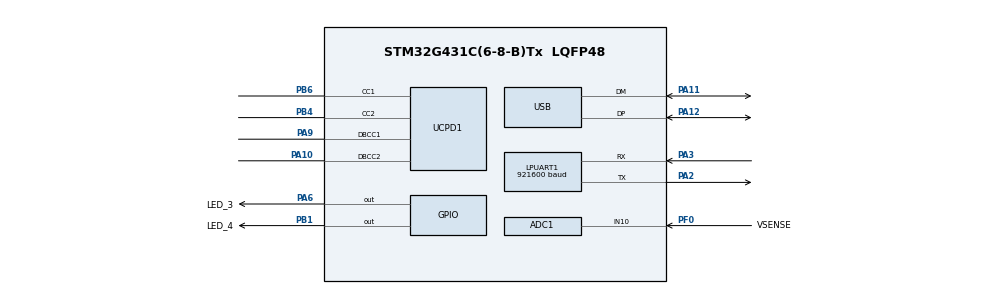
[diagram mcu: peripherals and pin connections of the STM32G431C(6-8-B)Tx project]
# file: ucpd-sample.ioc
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ADC1.Channel-0\#ChannelRegularConversion=ADC_CHANNEL_10
ADC1.ClockPrescaler=ADC_CLOCK_SYNC_PCLK_DIV4
ADC1.ContinuousConvMode=ENABLE
ADC1.NbrOfConversionFlag=1
ADC1.OffsetNumber-0\#ChannelRegularConversion=ADC_OFFSET_NONE
ADC1.Overrun=ADC_OVR_DATA_OVERWRITTEN
ADC1.Rank-0\#ChannelRegularConversion=1
ADC1.SamplingTime-0\#ChannelRegularConversion=ADC_SAMPLETIME_247CYCLES_5
ADC1.master=1
Dma.LPUART1_TX.0.Direction=DMA_MEMORY_TO_PERIPH
Dma.LPUART1_TX.0.EventEnable=DISABLE
Dma.LPUART1_TX.0.Instance=DMA1_Channel1
Dma.LPUART1_TX.0.MemDataAlignment=DMA_MDATAALIGN_BYTE
Dma.LPUART1_TX.0.MemInc=DMA_MINC_ENABLE
Dma.LPUART1_TX.0.Mode=DMA_NORMAL
Dma.LPUART1_TX.0.PeriphDataAlignment=DMA_PDATAALIGN_BYTE
Dma.LPUART1_TX.0.PeriphInc=DMA_PINC_DISABLE
Dma.LPUART1_TX.0.Polarity=HAL_DMAMUX_REQ_GEN_RISING
Dma.LPUART1_TX.0.Priority=DMA_PRIORITY_LOW
Dma.LPUART1_TX.0.RequestNumber=1
Dma.LPUART1_TX.0.SignalID=NONE
Dma.LPUART1_TX.0.SyncEnable=DISABLE
Dma.LPUART1_TX.0.SyncPolarity=HAL_DMAMUX_SYNC_NO_EVENT
Dma.LPUART1_TX.0.SyncRequestNumber=1
Dma.LPUART1_TX.0.SyncSignalID=NONE
Dma.Request0=LPUART1_TX
Dma.Request1=UCPD1_RX
Dma.Request2=UCPD1_TX
Dma.UCPD1_RX.1.Direction=DMA_PERIPH_TO_MEMORY
Dma.UCPD1_RX.1.EventEnable=DISABLE
Dma.UCPD1_RX.1.Instance=DMA1_Channel2
Dma.UCPD1_RX.1.MemDataAlignment=DMA_MDATAALIGN_BYTE
Dma.UCPD1_RX.1.MemInc=DMA_MINC_ENABLE
Dma.UCPD1_RX.1.Mode=DMA_NORMAL
Dma.UCPD1_RX.1.PeriphDataAlignment=DMA_PDATAALIGN_BYTE
Dma.UCPD1_RX.1.PeriphInc=DMA_PINC_DISABLE
Dma.UCPD1_RX.1.Polarity=HAL_DMAMUX_REQ_GEN_RISING
Dma.UCPD1_RX.1.Priority=DMA_PRIORITY_LOW
Dma.UCPD1_RX.1.RequestNumber=1
Dma.UCPD1_RX.1.SignalID=NONE
Dma.UCPD1_RX.1.SyncEnable=DISABLE
Dma.UCPD1_RX.1.SyncPolarity=HAL_DMAMUX_SYNC_NO_EVENT
Dma.UCPD1_RX.1.SyncRequestNumber=1
Dma.UCPD1_RX.1.SyncSignalID=NONE
Dma.UCPD1_TX.2.Direction=DMA_MEMORY_TO_PERIPH
Dma.UCPD1_TX.2.EventEnable=DISABLE
Dma.UCPD1_TX.2.Instance=DMA1_Channel3
Dma.UCPD1_TX.2.MemDataAlignment=DMA_MDATAALIGN_BYTE
Dma.UCPD1_TX.2.MemInc=DMA_MINC_ENABLE
Dma.UCPD1_TX.2.Mode=DMA_NORMAL
Dma.UCPD1_TX.2.PeriphDataAlignment=DMA_PDATAALIGN_BYTE
Dma.UCPD1_TX.2.PeriphInc=DMA_PINC_DISABLE
Dma.UCPD1_TX.2.Polarity=HAL_DMAMUX_REQ_GEN_RISING
Dma.UCPD1_TX.2.Priority=DMA_PRIORITY_LOW
Dma.UCPD1_TX.2.RequestNumber=1
Dma.UCPD1_TX.2.SignalID=NONE
Dma.UCPD1_TX.2.SyncEnable=DISABLE
Dma.UCPD1_TX.2.SyncPolarity=HAL_DMAMUX_SYNC_NO_EVENT
Dma.UCPD1_TX.2.SyncRequestNumber=1
Dma.UCPD1_TX.2.SyncSignalID=NONE
FREERTOS.Tasks01=defaultTask,24,128,StartDefaultTask,Default,NULL,Dynamic,NULL,NULL
FREERTOS.configTOTAL_HEAP_SIZE=7000
FREERTOS.configUSE_NEWLIB_REENTRANT=1
GUI_INTERFACE.HWBoardVersionName=G4_UCPD01
GUI_INTERFACE.PDTypeName=Sink
LPUART1.BaudRate=921600
Mcu.Family=STM32G4
Mcu.Name=STM32G431C(6-8-B)Tx
Mcu.Package=LQFP48
Mcu.UserConstants=VDDA_APPLI,3300
NVIC.DMA1_Channel1_IRQn=true\:5\:0\:false\:false\:true\:true\:false\:true\:true
NVIC.DMA1_Channel2_IRQn=true\:5\:0\:false\:false\:true\:true\:false\:true\:true
NVIC.DMA1_Channel3_IRQn=true\:5\:0\:false\:false\:true\:true\:false\:true\:true
NVIC.LPUART1_IRQn=true\:5\:0\:false\:false\:true\:true\:false\:true\:true
NVIC.PriorityGroup=NVIC_PRIORITYGROUP_4
NVIC.UCPD1_IRQn=true\:5\:0\:false\:false\:true\:true\:true\:false\:true
PA10.Mode=EnableDeadBattery
PA10.Signal=UCPD1_DBCC2
PA11.Mode=Device
PA11.Signal=USB_DM
PA12.Mode=Device
PA12.Signal=USB_DP
PA13.Mode=Serial_Wire
PA13.Signal=SYS_JTMS-SWDIO
PA14.Mode=Serial_Wire
PA14.Signal=SYS_JTCK-SWCLK
PA2.Mode=Asynchronous
PA2.Signal=LPUART1_TX
PA3.Mode=Asynchronous
PA3.Signal=LPUART1_RX
PA6.GPIO_Label=LED_3
PA6.PinState=GPIO_PIN_SET
PA6.Signal=GPIO_Output
PA9.Mode=EnableDeadBattery
PA9.Signal=UCPD1_DBCC1
PB1.GPIO_Label=LED_4
PB1.PinState=GPIO_PIN_SET
PB1.Signal=GPIO_Output
PB4.Mode=Sink_AllSignals
PB4.Signal=UCPD1_CC2
PB6.Mode=Sink_AllSignals
PB6.Signal=UCPD1_CC1
PF0-OSC_IN.GPIO_Label=VSENSE
PF0-OSC_IN.Mode=IN10-Single-Ended
PF0-OSC_IN.Signal=ADC1_IN10
ProjectManager.HeapSize=0x500
ProjectManager.StackSize=0x400
ProjectManager.TargetToolchain=CMake
RCC.AHBFreq_Value=16000000
RCC.APB1Freq_Value=16000000
RCC.APB1TimFreq_Value=16000000
RCC.APB2Freq_Value=16000000
RCC.APB2TimFreq_Value=16000000
RCC.CortexFreq_Value=16000000
RCC.EXTERNAL_CLOCK_VALUE=12288000
RCC.HCLKFreq_Value=16000000
RCC.HSE_VALUE=8000000
RCC.HSI48_VALUE=48000000
RCC.HSI_VALUE=16000000
RCC.LSE_VALUE=32768
RCC.PLLN=12
RCC.PLLQ=RCC_PLLQ_DIV4
RCC.SYSCLKFreq_VALUE=16000000
RCC.USBFreq_Value=48000000
RCC.VCOOutputFreq_Value=192000000
USBPD.PORT0_NB_SINKPDO=4
USBPD.USBPD_PORT0_PDO_SNK_BATTERY_SET_MAX_VOLTAGE_3=15000
USBPD.USBPD_PORT0_PDO_SNK_BATTERY_SET_OP_POWER_3=1000
USBPD.USBPD_PORT0_PDO_SNK_FIXED_SET_OP_CURRENT_0=3000
USBPD.USBPD_PORT0_PDO_SNK_FIXED_SET_OP_CURRENT_1=2000
USBPD.USBPD_PORT0_PDO_SNK_FIXED_SET_OP_CURRENT_2=2000
USBPD.USBPD_PORT0_PDO_SNK_FIXED_SET_VOLTAGE_1=9000
USBPD.USBPD_PORT0_PDO_SNK_FIXED_SET_VOLTAGE_2=15000
USBPD.USBPD_PORT0_PDO_SNK_NB=4
USBPD.USBPD_PORT0_PDO_SNK_TYPE_2=USBPD_PDO_TYPE_FIXED
USBPD.USBPD_PORT0_PDO_SNK_TYPE_3=USBPD_PDO_TYPE_VARIABLE
USBPD.USBPD_PORT0_PDO_SNK_VARIABLE_SET_MAX_VOLTAGE_2=15000
USBPD.USBPD_PORT0_PDO_SNK_VARIABLE_SET_MIN_VOLTAGE_3=15000
USBPD.USBPD_PORT0_PDO_SNK_VARIABLE_SET_OP_CURRENT_2=1500
USBPD.USBPD_PORT0_PDO_SNK_VARIABLE_SET_OP_CURRENT_3=1000
VP_FREERTOS_VS_CMSIS_V2.Mode=CMSIS_V2
VP_GUI_INTERFACE_VS_gui_interface.Mode=GUI_INTERFACE
VP_SYS_VS_DBSignals.Mode=DisableDeadBatterySignals
VP_TRACER_EMB_VS_traceremb_lpuart1.Mode=TRACER_EMB_LPUART1
VP_USBPD_VS_PD3MINSNK.Mode=PD3_Min_Snk
VP_USBPD_VS_USBPD1.Mode=USBPD_P0
VP_USBPD_VS_usbpd_tim1.Mode=TIM1
VP_USBPD_VS_usbpd_traceremb.Mode=TRACER_EMB
board=custom

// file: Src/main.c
/* USER CODE BEGIN Header */
/**
  ******************************************************************************
  * @file           : main.c
  * @brief          : Main program body
  ******************************************************************************
  * @attention
  *
  * Copyright (c) 2024 STMicroelectronics.
  * All rights reserved.
  *
  * This software is licensed under terms that can be found in the LICENSE file
  * in the root directory of this software component.
  * If no LICENSE file comes with this software, it is provided AS-IS.
  *
  ******************************************************************************
  */
/* USER CODE END Header */
#include "main.h"
#include "cmsis_os.h"
#include "usbpd.h"

PCD_HandleTypeDef hpcd_USB_FS;

/* Definitions for defaultTask */
osThreadId_t defaultTaskHandle;
const osThreadAttr_t defaultTask_attributes = {
  .name = "defaultTask",
  .priority = (osPriority_t) osPriorityNormal,
  .stack_size = 128 * 4
};

void SystemClock_Config(void);
static void MX_GPIO_Init(void);
static void MX_DMA_Init(void);
static void MX_LPUART1_UART_Init(void);
static void MX_USB_PCD_Init(void);
static void MX_UCPD1_Init(void);
static void MX_ADC1_Init(void);
void StartDefaultTask(void *argument);

int main(void)
{

  /* MCU Configuration--------------------------------------------------------*/

  /* Reset of all peripherals, Initializes the Flash interface and the Systick. */
  HAL_Init();

  /* Configure the system clock */
  SystemClock_Config();

  /* Initialize all configured peripherals */
  MX_GPIO_Init();
  MX_DMA_Init();
  MX_LPUART1_UART_Init();
  MX_USB_PCD_Init();
  HAL_Delay(1000);
  MX_UCPD1_Init();
  MX_ADC1_Init();

  /* Init scheduler */
  osKernelInitialize();
  /* USBPD initialisation ---------------------------------*/
  // MX_USBPD_Init();

  /* Create the thread(s) */
  /* creation of defaultTask */
  defaultTaskHandle = osThreadNew(StartDefaultTask, NULL, &defaultTask_attributes);

  /* Start scheduler */
  osKernelStart();

  /* We should never get here as control is now taken by the scheduler */

  /* Infinite loop */
  while (1)
  {

  }
}

void SystemClock_Config(void)
{
  LL_FLASH_SetLatency(LL_FLASH_LATENCY_0);
  while(LL_FLASH_GetLatency() != LL_FLASH_LATENCY_0)
  {
  }
  LL_PWR_SetRegulVoltageScaling(LL_PWR_REGU_VOLTAGE_SCALE1);
  LL_RCC_HSI_Enable();
   /* Wait till HSI is ready */
  while(LL_RCC_HSI_IsReady() != 1)
  {
  }

  LL_RCC_HSI_SetCalibTrimming(64);
  LL_RCC_PLL_ConfigDomain_48M(LL_RCC_PLLSOURCE_HSI, LL_RCC_PLLM_DIV_1, 12, LL_RCC_PLLQ_DIV_4);
  LL_RCC_PLL_EnableDomain_48M();
  LL_RCC_PLL_Enable();
   /* Wait till PLL is ready */
  while(LL_RCC_PLL_IsReady() != 1)
  {
  }

  LL_RCC_SetSysClkSource(LL_RCC_SYS_CLKSOURCE_HSI);
   /* Wait till System clock is ready */
  while(LL_RCC_GetSysClkSource() != LL_RCC_SYS_CLKSOURCE_STATUS_HSI)
  {
  }

  /* Set AHB prescaler*/
  LL_RCC_SetAHBPrescaler(LL_RCC_SYSCLK_DIV_1);
  LL_RCC_SetAPB1Prescaler(LL_RCC_APB1_DIV_1);
  LL_RCC_SetAPB2Prescaler(LL_RCC_APB2_DIV_1);
  LL_SetSystemCoreClock(16000000);

   /* Update the time base */
  if (HAL_InitTick (TICK_INT_PRIORITY) != HAL_OK)
  {
    Error_Handler();
  }
}

static void MX_ADC1_Init(void)
{

  LL_ADC_InitTypeDef ADC_InitStruct = {0};
  LL_ADC_REG_InitTypeDef ADC_REG_InitStruct = {0};
  LL_ADC_CommonInitTypeDef ADC_CommonInitStruct = {0};

  LL_GPIO_InitTypeDef GPIO_InitStruct = {0};

  LL_RCC_SetADCClockSource(LL_RCC_ADC12_CLKSOURCE_SYSCLK);

  /* Peripheral clock enable */
  LL_AHB2_GRP1_EnableClock(LL_AHB2_GRP1_PERIPH_ADC12);

  LL_AHB2_GRP1_EnableClock(LL_AHB2_GRP1_PERIPH_GPIOF);
  /**ADC1 GPIO Configuration
  PF0-OSC_IN   ------> ADC1_IN10
  */
  GPIO_InitStruct.Pin = VSENSE_Pin;
  GPIO_InitStruct.Mode = LL_GPIO_MODE_ANALOG;
  GPIO_InitStruct.Pull = LL_GPIO_PULL_NO;
  LL_GPIO_Init(VSENSE_GPIO_Port, &GPIO_InitStruct);

  /** Common config
  */
  ADC_InitStruct.Resolution = LL_ADC_RESOLUTION_12B;
  ADC_InitStruct.DataAlignment = LL_ADC_DATA_ALIGN_RIGHT;
  ADC_InitStruct.LowPowerMode = LL_ADC_LP_MODE_NONE;
  LL_ADC_Init(ADC1, &ADC_InitStruct);
  ADC_REG_InitStruct.TriggerSource = LL_ADC_REG_TRIG_SOFTWARE;
  ADC_REG_InitStruct.SequencerLength = LL_ADC_REG_SEQ_SCAN_DISABLE;
  ADC_REG_InitStruct.SequencerDiscont = LL_ADC_REG_SEQ_DISCONT_DISABLE;
  ADC_REG_InitStruct.ContinuousMode = LL_ADC_REG_CONV_CONTINUOUS;
  ADC_REG_InitStruct.DMATransfer = LL_ADC_REG_DMA_TRANSFER_NONE;
  ADC_REG_InitStruct.Overrun = LL_ADC_REG_OVR_DATA_OVERWRITTEN;
  LL_ADC_REG_Init(ADC1, &ADC_REG_InitStruct);
  LL_ADC_SetGainCompensation(ADC1, 0);
  LL_ADC_SetOverSamplingScope(ADC1, LL_ADC_OVS_DISABLE);
  ADC_CommonInitStruct.CommonClock = LL_ADC_CLOCK_SYNC_PCLK_DIV4;
  ADC_CommonInitStruct.Multimode = LL_ADC_MULTI_INDEPENDENT;
  LL_ADC_CommonInit(__LL_ADC_COMMON_INSTANCE(ADC1), &ADC_CommonInitStruct);

  /* Disable ADC deep power down (enabled by default after reset state) */
  LL_ADC_DisableDeepPowerDown(ADC1);
  /* Enable ADC internal voltage regulator */
  LL_ADC_EnableInternalRegulator(ADC1);
  /* Delay for ADC internal voltage regulator stabilization. */
  /* Compute number of CPU cycles to wait for, from delay in us. */
  /* Note: Variable divided by 2 to compensate partially */
  /* CPU processing cycles (depends on compilation optimization). */
  /* Note: If system core clock frequency is below 200kHz, wait time */
  /* is only a few CPU processing cycles. */
  uint32_t wait_loop_index;
  wait_loop_index = ((LL_ADC_DELAY_INTERNAL_REGUL_STAB_US * (SystemCoreClock / (100000 * 2))) / 10);
  while(wait_loop_index != 0)
  {
    wait_loop_index--;
  }

  /** Configure Regular Channel
  */
  LL_ADC_REG_SetSequencerRanks(ADC1, LL_ADC_REG_RANK_1, LL_ADC_CHANNEL_10);
  LL_ADC_SetChannelSamplingTime(ADC1, LL_ADC_CHANNEL_10, LL_ADC_SAMPLINGTIME_247CYCLES_5);
  LL_ADC_SetChannelSingleDiff(ADC1, LL_ADC_CHANNEL_10, LL_ADC_SINGLE_ENDED);
  /* USER CODE BEGIN ADC1_Init 2 */
  LL_ADC_StartCalibration(ADC1, LL_ADC_SINGLE_ENDED);
  LL_ADC_REG_StartConversion(ADC1);
  /* USER CODE END ADC1_Init 2 */

}

static void MX_LPUART1_UART_Init(void)
{

  LL_LPUART_InitTypeDef LPUART_InitStruct = {0};

  LL_GPIO_InitTypeDef GPIO_InitStruct = {0};

  LL_RCC_SetLPUARTClockSource(LL_RCC_LPUART1_CLKSOURCE_PCLK1);

  /* Peripheral clock enable */
  LL_APB1_GRP2_EnableClock(LL_APB1_GRP2_PERIPH_LPUART1);

  LL_AHB2_GRP1_EnableClock(LL_AHB2_GRP1_PERIPH_GPIOA);
  /**LPUART1 GPIO Configuration
  PA2   ------> LPUART1_TX
  PA3   ------> LPUART1_RX
  */
  GPIO_InitStruct.Pin = LL_GPIO_PIN_2;
  GPIO_InitStruct.Mode = LL_GPIO_MODE_ALTERNATE;
  GPIO_InitStruct.Speed = LL_GPIO_SPEED_FREQ_LOW;
  GPIO_InitStruct.OutputType = LL_GPIO_OUTPUT_PUSHPULL;
  GPIO_InitStruct.Pull = LL_GPIO_PULL_NO;
  GPIO_InitStruct.Alternate = LL_GPIO_AF_12;
  LL_GPIO_Init(GPIOA, &GPIO_InitStruct);

  GPIO_InitStruct.Pin = LL_GPIO_PIN_3;
  GPIO_InitStruct.Mode = LL_GPIO_MODE_ALTERNATE;
  GPIO_InitStruct.Speed = LL_GPIO_SPEED_FREQ_LOW;
  GPIO_InitStruct.OutputType = LL_GPIO_OUTPUT_PUSHPULL;
  GPIO_InitStruct.Pull = LL_GPIO_PULL_NO;
  GPIO_InitStruct.Alternate = LL_GPIO_AF_12;
  LL_GPIO_Init(GPIOA, &GPIO_InitStruct);

  /* LPUART1 DMA Init */

  /* LPUART1_TX Init */
  LL_DMA_SetPeriphRequest(DMA1, LL_DMA_CHANNEL_1, LL_DMAMUX_REQ_LPUART1_TX);

  LL_DMA_SetDataTransferDirection(DMA1, LL_DMA_CHANNEL_1, LL_DMA_DIRECTION_MEMORY_TO_PERIPH);

  LL_DMA_SetChannelPriorityLevel(DMA1, LL_DMA_CHANNEL_1, LL_DMA_PRIORITY_LOW);

  LL_DMA_SetMode(DMA1, LL_DMA_CHANNEL_1, LL_DMA_MODE_NORMAL);

  LL_DMA_SetPeriphIncMode(DMA1, LL_DMA_CHANNEL_1, LL_DMA_PERIPH_NOINCREMENT);

  LL_DMA_SetMemoryIncMode(DMA1, LL_DMA_CHANNEL_1, LL_DMA_MEMORY_INCREMENT);

  LL_DMA_SetPeriphSize(DMA1, LL_DMA_CHANNEL_1, LL_DMA_PDATAALIGN_BYTE);

  LL_DMA_SetMemorySize(DMA1, LL_DMA_CHANNEL_1, LL_DMA_MDATAALIGN_BYTE);

  /* LPUART1 interrupt Init */
  NVIC_SetPriority(LPUART1_IRQn, NVIC_EncodePriority(NVIC_GetPriorityGrouping(),5, 0));
  NVIC_EnableIRQ(LPUART1_IRQn);

  LPUART_InitStruct.PrescalerValue = LL_LPUART_PRESCALER_DIV1;
  LPUART_InitStruct.BaudRate = 921600;
  LPUART_InitStruct.DataWidth = LL_LPUART_DATAWIDTH_8B;
  LPUART_InitStruct.StopBits = LL_LPUART_STOPBITS_1;
  LPUART_InitStruct.Parity = LL_LPUART_PARITY_NONE;
  LPUART_InitStruct.TransferDirection = LL_LPUART_DIRECTION_TX_RX;
  LPUART_InitStruct.HardwareFlowControl = LL_LPUART_HWCONTROL_NONE;
  LL_LPUART_Init(LPUART1, &LPUART_InitStruct);
  LL_LPUART_SetTXFIFOThreshold(LPUART1, LL_LPUART_FIFOTHRESHOLD_1_8);
  LL_LPUART_SetRXFIFOThreshold(LPUART1, LL_LPUART_FIFOTHRESHOLD_1_8);
  LL_LPUART_DisableFIFO(LPUART1);

  LL_LPUART_Enable(LPUART1);

  /* Polling LPUART1 initialisation */
  while((!(LL_LPUART_IsActiveFlag_TEACK(LPUART1))) || (!(LL_LPUART_IsActiveFlag_REACK(LPUART1))))
  {
  }

}

static void MX_UCPD1_Init(void)
{

  LL_GPIO_InitTypeDef GPIO_InitStruct = {0};

  /* Peripheral clock enable */
  LL_APB1_GRP2_EnableClock(LL_APB1_GRP2_PERIPH_UCPD1);

  LL_AHB2_GRP1_EnableClock(LL_AHB2_GRP1_PERIPH_GPIOB);
  /**UCPD1 GPIO Configuration
  PB4   ------> UCPD1_CC2
  PB6   ------> UCPD1_CC1
  */
  GPIO_InitStruct.Pin = LL_GPIO_PIN_4;
  GPIO_InitStruct.Mode = LL_GPIO_MODE_ANALOG;
  GPIO_InitStruct.Pull = LL_GPIO_PULL_NO;
  LL_GPIO_Init(GPIOB, &GPIO_InitStruct);

  GPIO_InitStruct.Pin = LL_GPIO_PIN_6;
  GPIO_InitStruct.Mode = LL_GPIO_MODE_ANALOG;
  GPIO_InitStruct.Pull = LL_GPIO_PULL_NO;
  LL_GPIO_Init(GPIOB, &GPIO_InitStruct);

  /* UCPD1 DMA Init */

  /* UCPD1_RX Init */
  LL_DMA_SetPeriphRequest(DMA1, LL_DMA_CHANNEL_2, LL_DMAMUX_REQ_UCPD1_RX);

  LL_DMA_SetDataTransferDirection(DMA1, LL_DMA_CHANNEL_2, LL_DMA_DIRECTION_PERIPH_TO_MEMORY);

  LL_DMA_SetChannelPriorityLevel(DMA1, LL_DMA_CHANNEL_2, LL_DMA_PRIORITY_LOW);

  LL_DMA_SetMode(DMA1, LL_DMA_CHANNEL_2, LL_DMA_MODE_NORMAL);

  LL_DMA_SetPeriphIncMode(DMA1, LL_DMA_CHANNEL_2, LL_DMA_PERIPH_NOINCREMENT);

  LL_DMA_SetMemoryIncMode(DMA1, LL_DMA_CHANNEL_2, LL_DMA_MEMORY_INCREMENT);

  LL_DMA_SetPeriphSize(DMA1, LL_DMA_CHANNEL_2, LL_DMA_PDATAALIGN_BYTE);

  LL_DMA_SetMemorySize(DMA1, LL_DMA_CHANNEL_2, LL_DMA_MDATAALIGN_BYTE);

  /* UCPD1_TX Init */
  LL_DMA_SetPeriphRequest(DMA1, LL_DMA_CHANNEL_3, LL_DMAMUX_REQ_UCPD1_TX);

  LL_DMA_SetDataTransferDirection(DMA1, LL_DMA_CHANNEL_3, LL_DMA_DIRECTION_MEMORY_TO_PERIPH);

  LL_DMA_SetChannelPriorityLevel(DMA1, LL_DMA_CHANNEL_3, LL_DMA_PRIORITY_LOW);

  LL_DMA_SetMode(DMA1, LL_DMA_CHANNEL_3, LL_DMA_MODE_NORMAL);

  LL_DMA_SetPeriphIncMode(DMA1, LL_DMA_CHANNEL_3, LL_DMA_PERIPH_NOINCREMENT);

  LL_DMA_SetMemoryIncMode(DMA1, LL_DMA_CHANNEL_3, LL_DMA_MEMORY_INCREMENT);

  LL_DMA_SetPeriphSize(DMA1, LL_DMA_CHANNEL_3, LL_DMA_PDATAALIGN_BYTE);

  LL_DMA_SetMemorySize(DMA1, LL_DMA_CHANNEL_3, LL_DMA_MDATAALIGN_BYTE);

  /* UCPD1 interrupt Init */
  NVIC_SetPriority(UCPD1_IRQn, NVIC_EncodePriority(NVIC_GetPriorityGrouping(),5, 0));
  NVIC_EnableIRQ(UCPD1_IRQn);

}

static void MX_USB_PCD_Init(void)
{

  hpcd_USB_FS.Instance = USB;
  hpcd_USB_FS.Init.dev_endpoints = 8;
  hpcd_USB_FS.Init.speed = PCD_SPEED_FULL;
  hpcd_USB_FS.Init.phy_itface = PCD_PHY_EMBEDDED;
  hpcd_USB_FS.Init.Sof_enable = DISABLE;
  hpcd_USB_FS.Init.low_power_enable = DISABLE;
  hpcd_USB_FS.Init.lpm_enable = DISABLE;
  hpcd_USB_FS.Init.battery_charging_enable = DISABLE;
  if (HAL_PCD_Init(&hpcd_USB_FS) != HAL_OK)
  {
    Error_Handler();
  }

}

static void MX_DMA_Init(void)
{

  /* Init with LL driver */
  /* DMA controller clock enable */
  LL_AHB1_GRP1_EnableClock(LL_AHB1_GRP1_PERIPH_DMAMUX1);
  LL_AHB1_GRP1_EnableClock(LL_AHB1_GRP1_PERIPH_DMA1);

  /* DMA interrupt init */
  /* DMA1_Channel1_IRQn interrupt configuration */
  NVIC_SetPriority(DMA1_Channel1_IRQn, NVIC_EncodePriority(NVIC_GetPriorityGrouping(),5, 0));
  NVIC_EnableIRQ(DMA1_Channel1_IRQn);
  /* DMA1_Channel2_IRQn interrupt configuration */
  NVIC_SetPriority(DMA1_Channel2_IRQn, NVIC_EncodePriority(NVIC_GetPriorityGrouping(),5, 0));
  NVIC_EnableIRQ(DMA1_Channel2_IRQn);
  /* DMA1_Channel3_IRQn interrupt configuration */
  NVIC_SetPriority(DMA1_Channel3_IRQn, NVIC_EncodePriority(NVIC_GetPriorityGrouping(),5, 0));
  NVIC_EnableIRQ(DMA1_Channel3_IRQn);

}

static void MX_GPIO_Init(void)
{
  LL_GPIO_InitTypeDef GPIO_InitStruct = {0};

  /* GPIO Ports Clock Enable */
  LL_AHB2_GRP1_EnableClock(LL_AHB2_GRP1_PERIPH_GPIOF);
  LL_AHB2_GRP1_EnableClock(LL_AHB2_GRP1_PERIPH_GPIOA);
  LL_AHB2_GRP1_EnableClock(LL_AHB2_GRP1_PERIPH_GPIOB);

  /**/
  LL_GPIO_SetOutputPin(LED_3_GPIO_Port, LED_3_Pin);

  /**/
  LL_GPIO_SetOutputPin(LED_4_GPIO_Port, LED_4_Pin);

  /**/
  GPIO_InitStruct.Pin = LED_3_Pin;
  GPIO_InitStruct.Mode = LL_GPIO_MODE_OUTPUT;
  GPIO_InitStruct.Speed = LL_GPIO_SPEED_FREQ_LOW;
  GPIO_InitStruct.OutputType = LL_GPIO_OUTPUT_PUSHPULL;
  GPIO_InitStruct.Pull = LL_GPIO_PULL_NO;
  LL_GPIO_Init(LED_3_GPIO_Port, &GPIO_InitStruct);

  /**/
  GPIO_InitStruct.Pin = LED_4_Pin;
  GPIO_InitStruct.Mode = LL_GPIO_MODE_OUTPUT;
  GPIO_InitStruct.Speed = LL_GPIO_SPEED_FREQ_LOW;
  GPIO_InitStruct.OutputType = LL_GPIO_OUTPUT_PUSHPULL;
  GPIO_InitStruct.Pull = LL_GPIO_PULL_NO;
  LL_GPIO_Init(LED_4_GPIO_Port, &GPIO_InitStruct);

}

void StartDefaultTask(void *argument)
{
  /* USER CODE BEGIN 5 */
  LL_GPIO_ResetOutputPin(LED_3_GPIO_Port, LED_3_Pin);
  /* Infinite loop */
  for(;;)
  {
    osDelay(1);
  }
  /* USER CODE END 5 */
}

void Error_Handler(void)
{
  __disable_irq();
  while (1)
  {
  }
}
